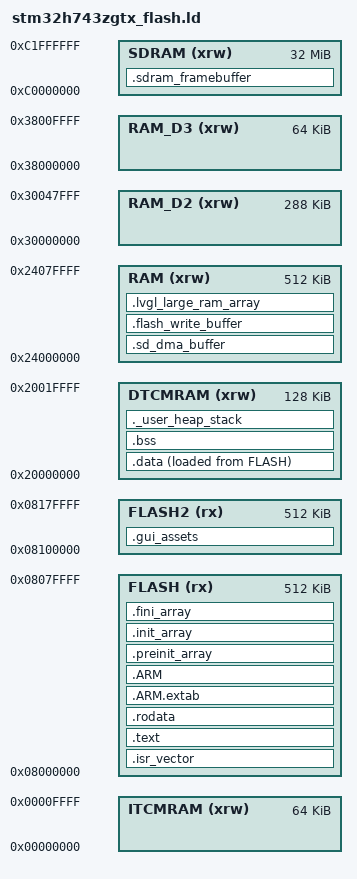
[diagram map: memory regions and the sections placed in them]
/*
******************************************************************************
**

**  File        : LinkerScript.ld
**
**  Author		: STM32CubeMX
**
**  Abstract    : Linker script for STM32H743ZGTx series
**                1024Kbytes FLASH and 1056Kbytes RAM
**
**                Set heap size, stack size and stack location according
**                to application requirements.
**
**                Set memory bank area and size if external memory is used.
**
**  Target      : STMicroelectronics STM32
**
**  Distribution: The file is distributed “as is,” without any warranty
**                of any kind.
**
*****************************************************************************
** @attention
**
** <h2><center>&copy; COPYRIGHT(c) 2019 STMicroelectronics</center></h2>
**
** Redistribution and use in source and binary forms, with or without modification,
** are permitted provided that the following conditions are met:
**   1. Redistributions of source code must retain the above copyright notice,
**      this list of conditions and the following disclaimer.
**   2. Redistributions in binary form must reproduce the above copyright notice,
**      this list of conditions and the following disclaimer in the documentation
**      and/or other materials provided with the distribution.
**   3. Neither the name of STMicroelectronics nor the names of its contributors
**      may be used to endorse or promote products derived from this software
**      without specific prior written permission.
**
** THIS SOFTWARE IS PROVIDED BY THE COPYRIGHT HOLDERS AND CONTRIBUTORS "AS IS"
** AND ANY EXPRESS OR IMPLIED WARRANTIES, INCLUDING, BUT NOT LIMITED TO, THE
** IMPLIED WARRANTIES OF MERCHANTABILITY AND FITNESS FOR A PARTICULAR PURPOSE ARE
** DISCLAIMED. IN NO EVENT SHALL THE COPYRIGHT HOLDER OR CONTRIBUTORS BE LIABLE
** FOR ANY DIRECT, INDIRECT, INCIDENTAL, SPECIAL, EXEMPLARY, OR CONSEQUENTIAL
** DAMAGES (INCLUDING, BUT NOT LIMITED TO, PROCUREMENT OF SUBSTITUTE GOODS OR
** SERVICES; LOSS OF USE, DATA, OR PROFITS; OR BUSINESS INTERRUPTION) HOWEVER
** CAUSED AND ON ANY THEORY OF LIABILITY, WHETHER IN CONTRACT, STRICT LIABILITY,
** OR TORT (INCLUDING NEGLIGENCE OR OTHERWISE) ARISING IN ANY WAY OUT OF THE USE
** OF THIS SOFTWARE, EVEN IF ADVISED OF THE POSSIBILITY OF SUCH DAMAGE.
**
*****************************************************************************
*/

/* Entry Point */
ENTRY(Reset_Handler)

/* Highest address of the user mode stack */
_estack = ORIGIN(DTCMRAM) + LENGTH(DTCMRAM);    /* end of RAM */
/* Generate a link error if heap and stack don't fit into RAM */
_Min_Heap_Size = 0x200;      /* required amount of heap  */
_Min_Stack_Size = 0x400; /* required amount of stack */

/* Specify the memory areas */
MEMORY
{
DTCMRAM (xrw)      : ORIGIN = 0x20000000, LENGTH = 128K
RAM (xrw)      : ORIGIN = 0x24000000, LENGTH = 512K
RAM_D2 (xrw)      : ORIGIN = 0x30000000, LENGTH = 288K
RAM_D3 (xrw)      : ORIGIN = 0x38000000, LENGTH = 64K
ITCMRAM (xrw)      : ORIGIN = 0x00000000, LENGTH = 64K
SDRAM (xrw)      :  ORIGIN = 0xC0000000, LENGTH = 32M
FLASH (rx)      : ORIGIN = 0x8000000, LENGTH = 512K
FLASH2 (rx)      : ORIGIN = 0x8100000, LENGTH = 512K
}

/* Define output sections */
SECTIONS
{
  /* The startup code goes first into FLASH */
  .isr_vector :
  {
    . = ALIGN(4);
    KEEP(*(.isr_vector)) /* Startup code */
    . = ALIGN(4);
  } >FLASH

  /* The program code and other data goes into FLASH */
  .text :
  {
    . = ALIGN(4);
    *(.text)           /* .text sections (code) */
    *(.text*)          /* .text* sections (code) */
    *(.glue_7)         /* glue arm to thumb code */
    *(.glue_7t)        /* glue thumb to arm code */
    *(.eh_frame)

    KEEP (*(.init))
    KEEP (*(.fini))

    . = ALIGN(4);
    _etext = .;        /* define a global symbols at end of code */
  } >FLASH

  /* Constant data goes into FLASH */
  /* SquareLine 图片与自定义字体的只读资源。在匹配到下面的.rodata之前先取走。 */
  .gui_assets :
  {
    . = ALIGN(4);

    *(.rodata.ui_img_*)
    *(.rodata.glyph_*)
    *(.rodata.cmaps)
    *(.rodata.kern_*)
    *(.rodata.ui_font_Number)

    . = ALIGN(4);
  } >FLASH2

  .rodata :
  {
    . = ALIGN(4);
    *(.rodata)         /* .rodata sections (constants, strings, etc.) */
    *(.rodata*)        /* .rodata* sections (constants, strings, etc.) */
    . = ALIGN(4);
  } >FLASH

  .ARM.extab   : { *(.ARM.extab* .gnu.linkonce.armextab.*) } >FLASH
  .ARM : {
    __exidx_start = .;
    *(.ARM.exidx*)
    __exidx_end = .;
  } >FLASH

  .preinit_array     :
  {
    PROVIDE_HIDDEN (__preinit_array_start = .);
    KEEP (*(.preinit_array*))
    PROVIDE_HIDDEN (__preinit_array_end = .);
  } >FLASH
  .init_array :
  {
    PROVIDE_HIDDEN (__init_array_start = .);
    KEEP (*(SORT(.init_array.*)))
    KEEP (*(.init_array*))
    PROVIDE_HIDDEN (__init_array_end = .);
  } >FLASH
  .fini_array :
  {
    PROVIDE_HIDDEN (__fini_array_start = .);
    KEEP (*(SORT(.fini_array.*)))
    KEEP (*(.fini_array*))
    PROVIDE_HIDDEN (__fini_array_end = .);
  } >FLASH

  /* used by the startup to initialize data */
  _sidata = LOADADDR(.data);

  /* Initialized data sections goes into RAM, load LMA copy after code */
  .data : 
  {
    . = ALIGN(4);
    _sdata = .;        /* create a global symbol at data start */
    *(.data)           /* .data sections */
    *(.data*)          /* .data* sections */

    . = ALIGN(4);
    _edata = .;        /* define a global symbol at data end */
  } >DTCMRAM AT> FLASH

  
  /* Uninitialized data section */
  . = ALIGN(4);
  .bss :
  {
    /* This is used by the startup in order to initialize the .bss secion */
    _sbss = .;         /* define a global symbol at bss start */
    __bss_start__ = _sbss;
    *(.bss)
    *(.bss*)
    *(COMMON)

    . = ALIGN(4);
    _ebss = .;         /* define a global symbol at bss end */
    __bss_end__ = _ebss;
  } >DTCMRAM

  /*
   * SDMMC 的内部 DMA 必须访问 AXI SRAM，不能使用默认位于 DTCMRAM 的 .bss。
   * 此段由每个用户在第一次 DMA 前完整写入，故设为 NOLOAD；32 字节对齐避免
   * Cortex-M7 D-Cache Clean/Invalidate 操作覆盖同一 cache line 的相邻变量。
   */
  .sd_dma_buffer (NOLOAD) :
  {
    . = ALIGN(32);
    *(.sd_dma_buffer)
    . = ALIGN(32);
  } >RAM

  /*
   * W25Q256 显式自检及未来 QSPI DMA 共用的 4 KiB 临时缓冲区。
   * 自检代码会在每次使用前填满或接收完整数据，故设为 NOLOAD；32 字节对齐
   * 让未来 DMA 的 Cache 维护不会触及相邻普通变量。
   */
  .flash_write_buffer (NOLOAD) :
  {
    . = ALIGN(32);
    *(.flash_write_buffer)
    . = ALIGN(32);
  } >RAM

  /* LVGL 大数组内存池可被 DMA2D 用作文字遮罩等源数据，必须位于 AXI RAM。 */
  .lvgl_large_ram_array (NOLOAD) :
  {
    . = ALIGN(32);
    *(.lvgl_large_ram_array)
    . = ALIGN(32);
  } >RAM

  /* SDRAM 帧缓冲区域：不加载、不自动清零，由拥有者在首次使用前完整写入。 */
  .sdram_framebuffer (NOLOAD) :
  {
    . = ALIGN(32);
    *(.sdram_framebuffer)
    . = ALIGN(32);
  } >SDRAM

  /* User_heap_stack section, used to check that there is enough RAM left */
  ._user_heap_stack :
  {
    . = ALIGN(8);
    PROVIDE ( end = . );
    PROVIDE ( _end = . );
    . = . + _Min_Heap_Size;
    . = . + _Min_Stack_Size;
    . = ALIGN(8);
  } >DTCMRAM

  

  /* Remove information from the standard libraries */
  /DISCARD/ :
  {
    libc.a ( * )
    libm.a ( * )
    libgcc.a ( * )
  }

}


